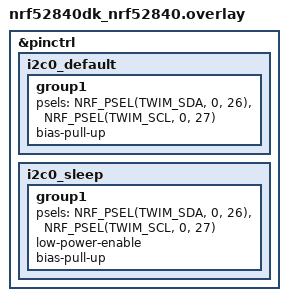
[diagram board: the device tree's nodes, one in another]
// Board-specific configuration for nRF52840DK
// Enable I2C pull-up resistors for better signal integrity

&pinctrl {
	i2c0_default: i2c0_default {
		group1 {
			psels = <NRF_PSEL(TWIM_SDA, 0, 26)>,
				<NRF_PSEL(TWIM_SCL, 0, 27)>;
			bias-pull-up;
		};
	};

	i2c0_sleep: i2c0_sleep {
		group1 {
			psels = <NRF_PSEL(TWIM_SDA, 0, 26)>,
				<NRF_PSEL(TWIM_SCL, 0, 27)>;
			low-power-enable;
			bias-pull-up;
		};
	};
};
